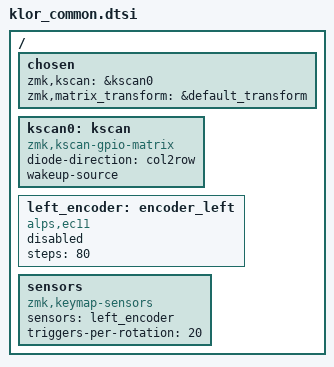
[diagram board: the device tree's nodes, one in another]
/*
 * KLOR polydactyl — gemeinsame Definitionen beider Haelften
 *
 * Abgeleitet von GEIGEIGEIST/zmk-config-klor (MIT).
 * Entfernt gegenueber dem Original: OLED-Node und chosen zephyr,display.
 * Der I2C-Bus bleibt aktiv — er versorgt jetzt das Trackpad.
 */

#include <dt-bindings/zmk/matrix_transform.h>

/ {
	chosen {
		zmk,kscan = &kscan0;
		zmk,matrix_transform = &default_transform;
	};

	kscan0: kscan {
		compatible = "zmk,kscan-gpio-matrix";
		diode-direction = "col2row";

		/*
		 * Ohne diese Property werden beim Eintritt in den Deep Sleep
		 * (CONFIG_ZMK_SLEEP) alle Matrix-GPIOs auf GPIO_DISCONNECTED
		 * gesetzt (siehe zmk_pm_suspend_devices() in app/src/pm.c) --
		 * dann kann kein Tastendruck mehr aufwecken, egal welcher.
		 */
		wakeup-source;
	};

	/*
	 * Nur die linke Haelfte bekommt einen Encoder. Die rechte Position
	 * ist vom Trackpad belegt, deshalb ist hier — anders als im Original —
	 * kein right_encoder definiert.
	 */
	left_encoder: encoder_left {
		compatible = "alps,ec11";
		steps = <80>;
		status = "disabled";
	};

	sensors: sensors {
		compatible = "zmk,keymap-sensors";
		sensors = <&left_encoder>;
		triggers-per-rotation = <20>;
	};
};
